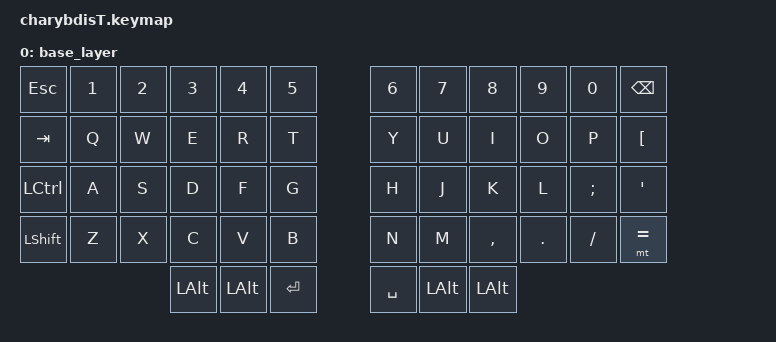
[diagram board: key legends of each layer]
/*
 * Copyright (c) 2020 The ZMK Contributors
 *
 * SPDX-License-Identifier: MIT
 */

#include <behaviors.dtsi>
#include <dt-bindings/led/led.h> /* bodo you need this to turn on ARGEEBEEH nowadays weh */
#include <dt-bindings/zmk/rgb.h>
#include <dt-bindings/zmk/keys.h>
#include <dt-bindings/zmk/bt.h>
// #include <dt-bindings/zmk/mouse.h>
//#include "mouse.dtsi"

#define DEFAULT 0-base

&spi3 {
    compatible = "nordic,nrf-spim";
    status = "okay";

    pinctrl-0 = <&spi3_default>;
    pinctrl-1 = <&spi3_sleep>;
    pinctrl-names = "default", "sleep";

    led_strip: ws2812@0 {
        compatible = "worldsemi,ws2812-spi";

        /* SPI */
        reg = <0>; /* ignored, but necessary for SPI bindings */
        spi-max-frequency = <4000000>;

        /* WS2812 */
        chain-length = <16>; /* number of LEDs << 8 each side */
        spi-one-frame = <0x70>;
        spi-zero-frame = <0x40>;
        color-mapping = <LED_COLOR_ID_GREEN
                            LED_COLOR_ID_RED
                            LED_COLOR_ID_BLUE>;

        };
};

/ {
    macros {
        henkan: henkan {
            compatible = "zmk,behavior-macro";
            #binding-cells = <0>;
            wait-ms = <40>;
            tap-ms = <40>;
            bindings
                = <&macro_press   &kp LALT>
                , <&macro_tap     &kp GRAVE>
                , <&macro_release &kp LALT>
                ;
        };
    };
        combos {
            compatible = "zmk,combos";
            timeout-ms = <100>;
            require-prior-idle-ms = <150>;

            combo_reset_left {
                key-positions = <14 15 16 25>;
                bindings = <&bootloader>;
            };

            combo_reset_right {
                key-positions = <19 20 21 34>;
                bindings = <&bootloader>;
            };

        };
};

/ {
        keymap {
                compatible = "zmk,keymap";

               base_layer {
// ------------------------------------------------------------------------------------------------------
// |  ESC  |  1  |  2  |  3  |  4  |  5  |      |  6  |  7  |  8  |  9  |  0  |  BSPC  |
// |  TAB  |  Q  |  W  |  E  |  R  |  T  |      |  Y  |  U  |  I  |  O  |  P  |  [   |
// | CTRL  |  A  |  S  |  D  |  F  |  G  |      |  H  |  J  |  K  |  L  |  ;  |  '     |
// | SHFT  |  Z  |  X  |  C  |  V  |  B  |      |  N  |  M  |  ,  |  .  |  /  | =  |
//                        | ALT  | LWR  |  SPC  |  RSE  | ALT  |

        bindings = <
        &kp ESC     &kp N1   &kp N2   &kp N3   &kp N4   &kp N5         &kp N6   &kp N7   &kp N8   &kp N9   &kp N0   &kp BSPC
        &kp TAB     &kp Q    &kp W    &kp E    &kp R    &kp T          &kp Y    &kp U    &kp I    &kp O    &kp P    &kp LBKT
        &kp LCTRL   &kp A    &kp S    &kp D    &kp F    &kp G          &kp H    &kp J    &kp K    &kp L    &kp SEMI &kp SQT
        &kp LSHFT   &kp Z    &kp X    &kp C    &kp V    &kp B          &kp N    &kp M    &kp COMMA &kp DOT  &kp FSLH &mt EQUAL
                                      &kp LALT &kp LALT    &kp RET        &kp SPACE      &kp LALT    &kp LALT
        >;
    };
};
